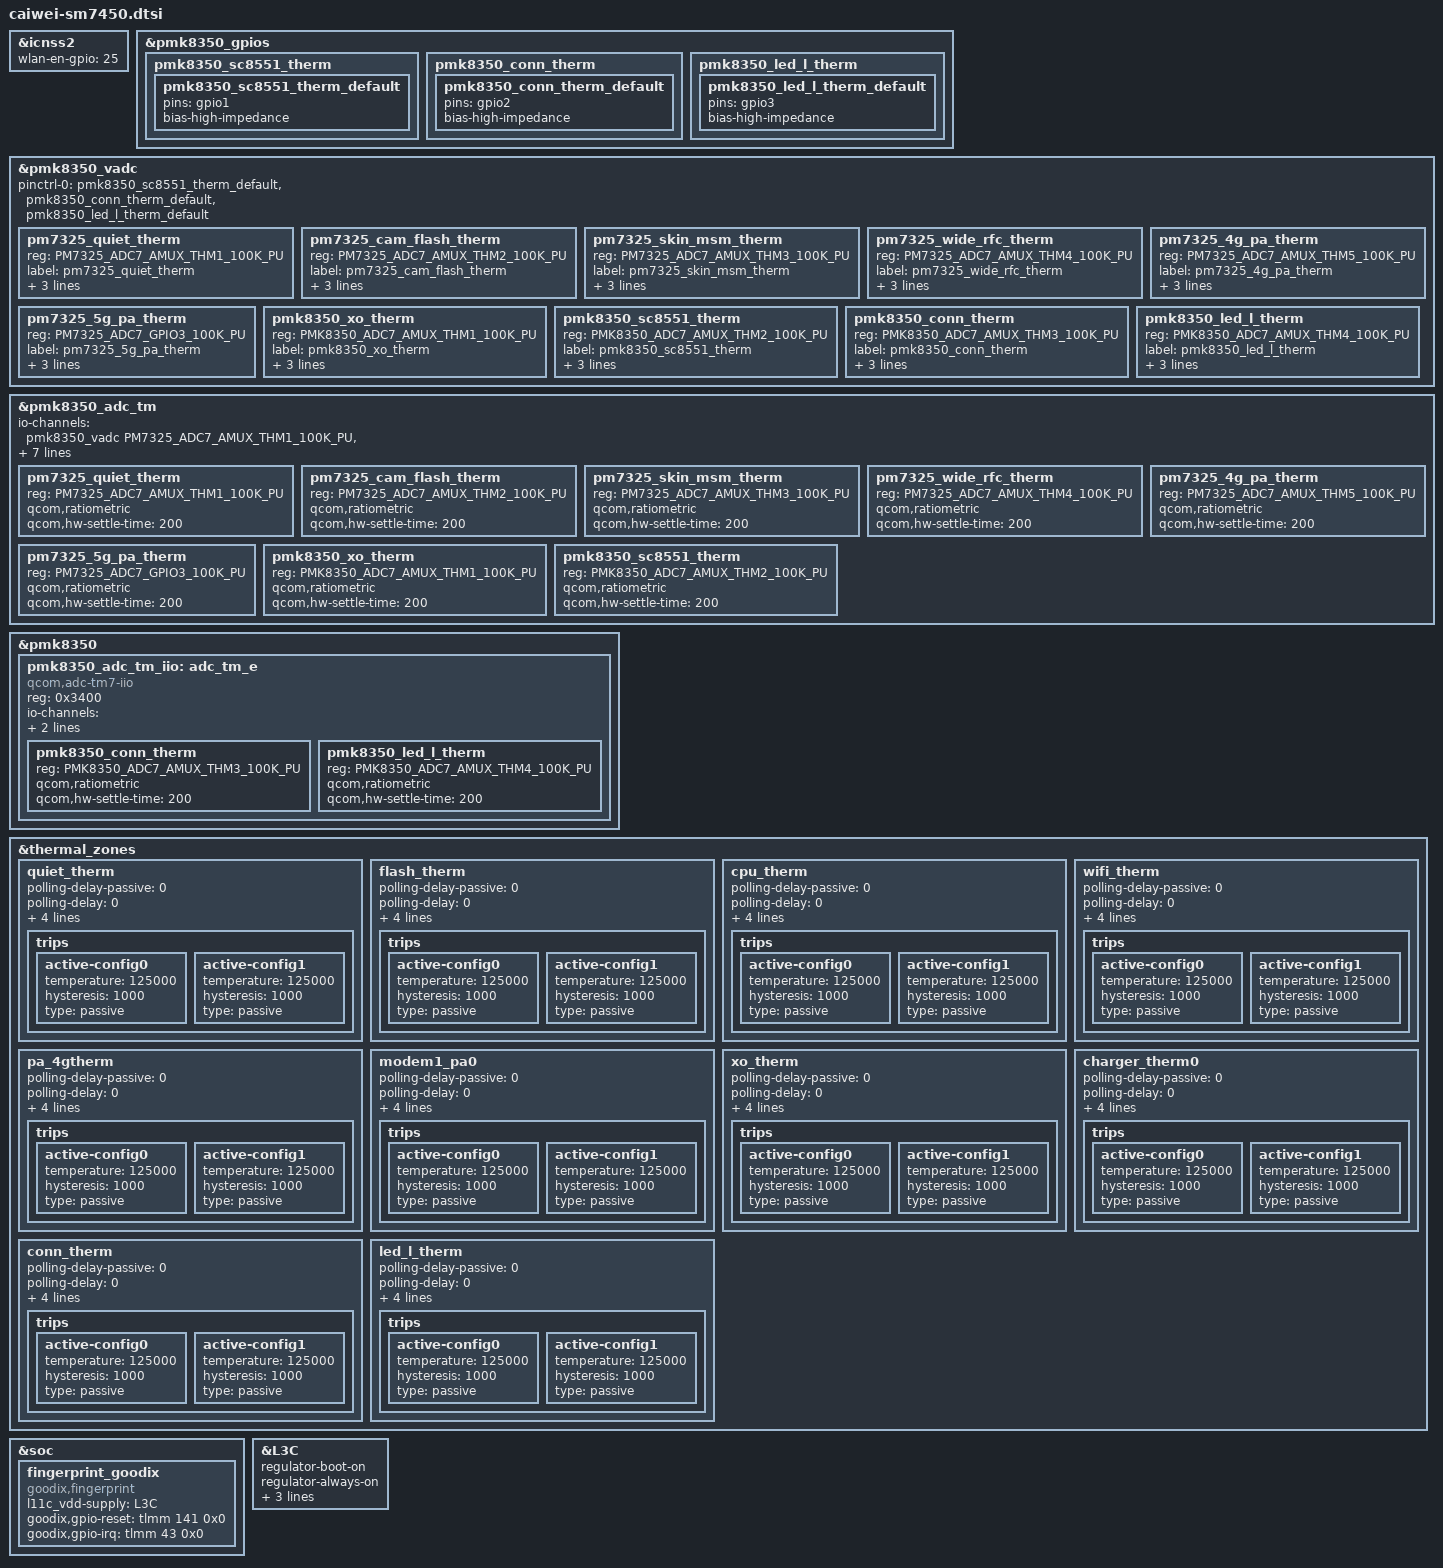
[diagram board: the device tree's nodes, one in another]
#include "xiaomi-sm7450-common.dtsi"

&icnss2 {
	wlan-en-gpio = <25>;
};

//disable PMK7450 GPIO_1_2_3 to fix the temp value inaccurate
&pmk8350_gpios {
    pmk8350_sc8551_therm {
        pmk8350_sc8551_therm_default: pmk8350_sc8551_therm_default {
            pins = "gpio1";
            bias-high-impedance;
        };
    };

    pmk8350_conn_therm {
        pmk8350_conn_therm_default: pmk8350_conn_therm_default {
            pins = "gpio2";
            bias-high-impedance;
        };
    };

    pmk8350_led_l_therm {
        pmk8350_led_l_therm_default: pmk8350_led_l_therm_default {
            pins = "gpio3";
            bias-high-impedance;
        };
    };
};

&pmk8350_vadc {
    pinctrl-names = "default";

    //disable PMK7450 GPIO_1_2_3 to fix the temp value inaccurate
    pinctrl-0 = <
        &pmk8350_sc8551_therm_default
        &pmk8350_conn_therm_default
        &pmk8350_led_l_therm_default>;

    pm7325_quiet_therm {
        reg = <PM7325_ADC7_AMUX_THM1_100K_PU>;
        label = "pm7325_quiet_therm";
        qcom,ratiometric;
        qcom,hw-settle-time = <200>;
        qcom,pre-scaling = <1 1>;
    };

    pm7325_cam_flash_therm {
        reg = <PM7325_ADC7_AMUX_THM2_100K_PU>;
        label = "pm7325_cam_flash_therm";
        qcom,ratiometric;
        qcom,hw-settle-time = <200>;
        qcom,pre-scaling = <1 1>;
    };

    pm7325_skin_msm_therm {
        reg = <PM7325_ADC7_AMUX_THM3_100K_PU>;
        label = "pm7325_skin_msm_therm";
        qcom,ratiometric;
        qcom,hw-settle-time = <200>;
        qcom,pre-scaling = <1 1>;
    };

    pm7325_wide_rfc_therm {
        reg = <PM7325_ADC7_AMUX_THM4_100K_PU>;
        label = "pm7325_wide_rfc_therm";
        qcom,ratiometric;
        qcom,hw-settle-time = <200>;
        qcom,pre-scaling = <1 1>;
    };

    pm7325_4g_pa_therm {
        reg = <PM7325_ADC7_AMUX_THM5_100K_PU>;
        label = "pm7325_4g_pa_therm";
        qcom,ratiometric;
        qcom,hw-settle-time = <200>;
        qcom,pre-scaling = <1 1>;
    };

    pm7325_5g_pa_therm {
        reg = <PM7325_ADC7_GPIO3_100K_PU>;
        label = "pm7325_5g_pa_therm";
        qcom,ratiometric;
        qcom,hw-settle-time = <200>;
        qcom,pre-scaling = <1 1>;
    };

    pmk8350_xo_therm {
        reg = <PMK8350_ADC7_AMUX_THM1_100K_PU>;
        label = "pmk8350_xo_therm";
        qcom,ratiometric;
        qcom,hw-settle-time = <200>;
        qcom,pre-scaling = <1 1>;
    };

    pmk8350_sc8551_therm {
        reg = <PMK8350_ADC7_AMUX_THM2_100K_PU>;
        label = "pmk8350_sc8551_therm";
        qcom,ratiometric;
        qcom,hw-settle-time = <200>;
        qcom,pre-scaling = <1 1>;
    };

    pmk8350_conn_therm {
        reg = <PMK8350_ADC7_AMUX_THM3_100K_PU>;
        label = "pmk8350_conn_therm";
        qcom,ratiometric;
        qcom,hw-settle-time = <200>;
        qcom,pre-scaling = <1 1>;
    };

    pmk8350_led_l_therm {
        reg = <PMK8350_ADC7_AMUX_THM4_100K_PU>;
        label = "pmk8350_led_l_therm";
        qcom,ratiometric;
        qcom,hw-settle-time = <200>;
        qcom,pre-scaling = <1 1>;
    };
};

&pmk8350_adc_tm {
    io-channels = <&pmk8350_vadc PM7325_ADC7_AMUX_THM1_100K_PU>,
                  <&pmk8350_vadc PM7325_ADC7_AMUX_THM2_100K_PU>,
                  <&pmk8350_vadc PM7325_ADC7_AMUX_THM3_100K_PU>,
                  <&pmk8350_vadc PM7325_ADC7_AMUX_THM4_100K_PU>,
                  <&pmk8350_vadc PM7325_ADC7_AMUX_THM5_100K_PU>,
                  <&pmk8350_vadc PM7325_ADC7_GPIO3_100K_PU>,
                  <&pmk8350_vadc PMK8350_ADC7_AMUX_THM1_100K_PU>,
                  <&pmk8350_vadc PMK8350_ADC7_AMUX_THM2_100K_PU>;

    pm7325_quiet_therm {
        reg = <PM7325_ADC7_AMUX_THM1_100K_PU>;
        qcom,ratiometric;
        qcom,hw-settle-time = <200>;
    };

    pm7325_cam_flash_therm {
        reg = <PM7325_ADC7_AMUX_THM2_100K_PU>;
        qcom,ratiometric;
        qcom,hw-settle-time = <200>;
    };

    pm7325_skin_msm_therm {
        reg = <PM7325_ADC7_AMUX_THM3_100K_PU>;
        qcom,ratiometric;
        qcom,hw-settle-time = <200>;
    };

    pm7325_wide_rfc_therm {
        reg = <PM7325_ADC7_AMUX_THM4_100K_PU>;
        qcom,ratiometric;
        qcom,hw-settle-time = <200>;
    };

    pm7325_4g_pa_therm {
        reg = <PM7325_ADC7_AMUX_THM5_100K_PU>;
        qcom,ratiometric;
        qcom,hw-settle-time = <200>;
    };

    pm7325_5g_pa_therm {
        reg = <PM7325_ADC7_GPIO3_100K_PU>;
        qcom,ratiometric;
        qcom,hw-settle-time = <200>;
    };

    pmk8350_xo_therm {
        reg = <PMK8350_ADC7_AMUX_THM1_100K_PU>;
        qcom,ratiometric;
        qcom,hw-settle-time = <200>;
    };

    pmk8350_sc8551_therm {
        reg = <PMK8350_ADC7_AMUX_THM2_100K_PU>;
        qcom,ratiometric;
        qcom,hw-settle-time = <200>;
    };
};

&pmk8350 {
    pmk8350_adc_tm_iio: adc_tm_e {
	compatible = "qcom,adc-tm7-iio";
	reg = <0x3400>;
	#thermal-sensor-cells = <1>;
	#address-cells = <1>;
	#size-cells = <0>;

	io-channels = <&pmk8350_vadc PMK8350_ADC7_AMUX_THM3_100K_PU>,
                      <&pmk8350_vadc PMK8350_ADC7_AMUX_THM4_100K_PU>;

	pmk8350_conn_therm {
            reg = <PMK8350_ADC7_AMUX_THM3_100K_PU>;
            qcom,ratiometric;
            qcom,hw-settle-time = <200>;
        };

        pmk8350_led_l_therm {
            reg = <PMK8350_ADC7_AMUX_THM4_100K_PU>;
            qcom,ratiometric;
            qcom,hw-settle-time = <200>;
        };
    };
};

&thermal_zones {
    quiet_therm {
        polling-delay-passive = <0>;
        polling-delay = <0>;
        thermal-governor = "user_space";
        thermal-sensors = <&pmk8350_adc_tm PM7325_ADC7_AMUX_THM1_100K_PU>;
        wake-capable-sensor;
        trips {
            active-config0 {
                temperature = <125000>;
                hysteresis = <1000>;
                type = "passive";
            };

            active-config1 {
                temperature = <125000>;
                hysteresis = <1000>;
                type = "passive";
            };
        };
    };

    flash_therm {
        polling-delay-passive = <0>;
        polling-delay = <0>;
        thermal-governor = "user_space";
        thermal-sensors = <&pmk8350_adc_tm PM7325_ADC7_AMUX_THM2_100K_PU>;
        wake-capable-sensor;
        trips {
            active-config0 {
                temperature = <125000>;
                hysteresis = <1000>;
                type = "passive";
            };

            active-config1 {
                temperature = <125000>;
                hysteresis = <1000>;
                type = "passive";
            };
        };
    };

    cpu_therm {
        polling-delay-passive = <0>;
        polling-delay = <0>;
        thermal-governor = "user_space";
        thermal-sensors = <&pmk8350_adc_tm PM7325_ADC7_AMUX_THM3_100K_PU>;
        wake-capable-sensor;
        trips {
            active-config0 {
                temperature = <125000>;
                hysteresis = <1000>;
                type = "passive";
            };

            active-config1 {
                temperature = <125000>;
                hysteresis = <1000>;
                type = "passive";
            };
        };
    };

    wifi_therm {
        polling-delay-passive = <0>;
        polling-delay = <0>;
        thermal-governor = "user_space";
        thermal-sensors = <&pmk8350_adc_tm PM7325_ADC7_AMUX_THM4_100K_PU>;
        wake-capable-sensor;
        trips {
            active-config0 {
                temperature = <125000>;
                hysteresis = <1000>;
                type = "passive";
            };

            active-config1 {
                temperature = <125000>;
                hysteresis = <1000>;
                type = "passive";
            };
        };
    };

    pa_4gtherm {
        polling-delay-passive = <0>;
        polling-delay = <0>;
        thermal-governor = "user_space";
        thermal-sensors = <&pmk8350_adc_tm PM7325_ADC7_AMUX_THM5_100K_PU>;
        wake-capable-sensor;
        trips {
            active-config0 {
                temperature = <125000>;
                hysteresis = <1000>;
                type = "passive";
            };

            active-config1 {
                temperature = <125000>;
                hysteresis = <1000>;
                type = "passive";
            };
        };
    };

    modem1_pa0 {
        polling-delay-passive = <0>;
        polling-delay = <0>;
        thermal-governor = "user_space";
        thermal-sensors = <&pmk8350_adc_tm PM7325_ADC7_GPIO3_100K_PU>;
        wake-capable-sensor;
        trips {
            active-config0 {
                temperature = <125000>;
                hysteresis = <1000>;
                type = "passive";
            };

            active-config1 {
                temperature = <125000>;
                hysteresis = <1000>;
                type = "passive";
            };
        };
    };

    xo_therm {
        polling-delay-passive = <0>;
        polling-delay = <0>;
        thermal-governor = "user_space";
        thermal-sensors = <&pmk8350_adc_tm PMK8350_ADC7_AMUX_THM1_100K_PU>;
        wake-capable-sensor;
        trips {
            active-config0 {
                temperature = <125000>;
                hysteresis = <1000>;
                type = "passive";
            };

            active-config1 {
                temperature = <125000>;
                hysteresis = <1000>;
                type = "passive";
            };
        };
    };

    charger_therm0 {
        polling-delay-passive = <0>;
        polling-delay = <0>;
        thermal-governor = "user_space";
        thermal-sensors = <&pmk8350_adc_tm PMK8350_ADC7_AMUX_THM2_100K_PU>;
        wake-capable-sensor;
        trips {
            active-config0 {
                temperature = <125000>;
                hysteresis = <1000>;
                type = "passive";
            };

            active-config1 {
                temperature = <125000>;
                hysteresis = <1000>;
                type = "passive";
            };
        };
    };

    conn_therm {
        polling-delay-passive = <0>;
        polling-delay = <0>;
        thermal-governor = "user_space";
        thermal-sensors = <&pmk8350_adc_tm_iio PMK8350_ADC7_AMUX_THM3_100K_PU>;
        wake-capable-sensor;
        trips {
            active-config0 {
                temperature = <125000>;
                hysteresis = <1000>;
                type = "passive";
            };

            active-config1 {
                temperature = <125000>;
                hysteresis = <1000>;
                type = "passive";
            };
        };
    };

    led_l_therm {
        polling-delay-passive = <0>;
        polling-delay = <0>;
        thermal-governor = "user_space";
        thermal-sensors = <&pmk8350_adc_tm_iio PMK8350_ADC7_AMUX_THM4_100K_PU>;
        wake-capable-sensor;
        trips {
            active-config0 {
                temperature = <125000>;
                hysteresis = <1000>;
                type = "passive";
            };

            active-config1 {
                temperature = <125000>;
                hysteresis = <1000>;
                type = "passive";
            };
        };
    };
};

&soc {
	fingerprint_goodix {
               status = "ok";
               compatible = "goodix,fingerprint";
               l11c_vdd-supply = <&L3C>;
               goodix,gpio-reset = <&tlmm 141 0x0>;
               goodix,gpio-irq = <&tlmm 43 0x0>;
       };

};

&L3C {
       regulator-boot-on;
       regulator-always-on;
       regulator-min-microvolt = <3200000>;
       regulator-max-microvolt = <3200000>;
       qcom,init-voltage = <3200000>;
};
